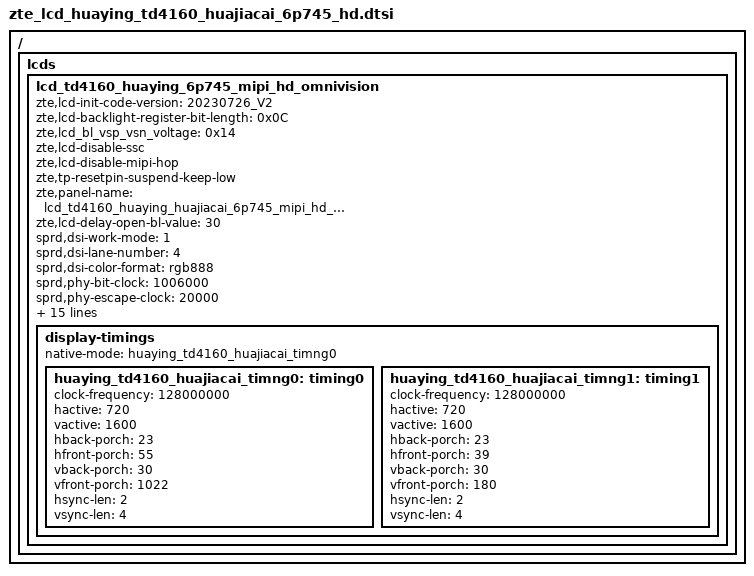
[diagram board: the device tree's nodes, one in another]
/ {
	fragment {
		target-path = "/";
		__overlay__ {
lcds {
		lcd_td4160_huaying_6p745_mipi_hd_omnivision: lcd_td4160_huaying_6p745_mipi_hd_omnivision {
			zte,lcd-init-code-version = "20230726_V2";
			zte,lcd-backlight-register-bit-length = <0x0C>;
			zte,lcd_bl_vsp_vsn_voltage = <0x14>;
			zte,lcd-disable-ssc;
			zte,lcd-disable-mipi-hop;
			zte,tp-resetpin-suspend-keep-low;
			zte,panel-name = "lcd_td4160_huaying_huajiacai_6p745_mipi_hd_omnivision";
			zte,lcd-delay-open-bl-value = <30>;

			sprd,dsi-work-mode = <1>; /* video burst mode*/
			sprd,dsi-lane-number = <4>;
			sprd,dsi-color-format = "rgb888";

			sprd,phy-bit-clock = <1006000>;	/* kbps */
			sprd,phy-escape-clock = <20000>;/* kHz */

			/*sprd,video-lp-cmd-enable = <1>;
			sprd,hporch-lp-disable = <1>;
			sprd,dpi-clk-div = <6>;*/

			sprd,width-mm = <70308>;
			sprd,height-mm = <156240>;

			sprd,esd-check-enable = <1>;/* 0:close , 1:open */
			sprd,esd-check-mode = <1>;/* 0:REG ,1:TE  */
			sprd,esd-check-period = <2000>;
			sprd,esd-check-register = <0x0A>;
			sprd,esd-check-value = <0x9C>;

			sprd,reset-on-sequence = <1 5>, <0 10>, <1 35>;
			sprd,reset-off-sequence = <0 5>;

			//sprd,use-dcs-write;
			sprd,initial-command = [
39 00 00 02 B0 00
39 00 00 07 B6 30 6A 00 86 C3 03
39 00 00 05 B7 31 00 00 00
39 00 00 07 B8 00 78 64 10 64 B4
39 00 00 07 B9 00 78 64 10 64 B4
39 00 00 07 BA 00 78 64 10 64 B4
39 00 00 04 BB 00 B4 A0
39 00 00 04 BC 00 B4 A0
39 00 00 04 BD 00 B4 A0
39 00 00 0E BE 07 00 00 00 00 00 00 00 00 00 00 00 00
39 00 00 19 C0 00 5F 22 06 40 00 1E 06 94 00 70 00 00 00 00 00 00 00 00 00 00 00 00 00
39 00 00 28 C1 30 41 50 FA 01 00 00 10 00 00 00 00 40 0F 00 00 00 00 00 00 00 00 00 00 00 00 00 00 00 00 00 00 00 00 00 00 00 00 00
39 00 00 F5 C2 05 80 58 12 0A 10 09 14 00 05 80 58 12 0A 10 07 13 00 05 80 58 12 05 06 5D 12 00 05 80 58 12 05 06 61 11 00 00 00 00 00 00 00 05 80 58 10 10 03 01 41 00 26 5F 00 00 00 08 00 00 00 00 11 00 26 5F 10 00 00 00 00 00 00 00 00 05 80 58 10 10 05 01 41 00 46 5D 00 00 00 08 00 00 00 00 11 00 46 5D 10 00 00 00 00 00 00 00 00 00 00 00 00 00 00 00 00 00 00 00 00 00 00 00 00 00 00 00 11 00 00 00 00 00 00 00 00 00 00 00 00 00 00 00 00 00 00 00 00 00 00 00 00 00 00 00 00 00 00 00 11 00 00 00 00 00 00 00 00 00 00 00 00 00 00 00 00 00 00 00 00 00 00 00 00 00 00 00 00 00 00 00 00 00 00 00 00 00 00 00 10 00 00 00 00 00 00 00 00 00 00 00 00 00 00 00 02 00 00 00 00 00 00 00 00 00 00 02 00 00 00 00 00 00 00 00 00 00 00 00 00 00 00 00 00 00 00
39 00 00 6A C3 00 00 41 81 01 06 69 00 00 00 20 00 00 00 41 81 01 66 75 00 00 00 20 02 00 00 42 81 00 F6 69 00 00 00 20 00 00 00 00 00 00 00 00 00 00 00 20 00 00 00 00 08 00 00 00 00 00 00 00 00 00 00 00 00 00 00 00 00 00 00 00 00 00 00 00 00 00 00 00 00 00 00 00 00 00 00 00 00 00 00 00 00 00 00 00 00 00 00 00 00 00 00 00 00 00
39 00 00 55 C4 00 00 0B 0F 00 00 00 00 00 00 54 53 00 21 1F 1D 1B 19 17 15 13 07 03 04 08 14 16 18 1A 1C 1E 20 22 00 53 54 00 00 00 00 00 00 10 0C 00 00 00 00 00 00 00 00 00 00 00 00 00 00 00 00 00 00 00 00 00 00 00 00 00 00 00 00 00 55 55 55 55 55 55 55 55 55 55 55
39 00 00 06 C5 08 00 00 00 00
39 00 00 4D C6 00 00 00 00 01 22 04 22 01 00 46 00 00 00 01 00 46 00 01 05 01 0B 01 35 FF 8F 06 C5 02 C0 0F 00 00 00 00 00 00 00 00 00 00 00 00 00 00 00 00 00 00 00 00 00 00 20 20 00 00 00 C0 11 00 00 00 10 10 00 00 00 01 00 50 00 33 03 00 00
39 00 00 1F CB 02 D0 01 80 00 00 00 00 00 00 00 00 00 00 00 00 00 00 00 00 00 00 40 70 00 00 00 00 00 FF
39 00 00 19 CE 5D 40 43 49 55 62 71 82 94 A8 B9 CB DB E9 F5 FC FF 04 00 04 04 00 00 00
39 00 00 02 CF 00
39 00 00 15 D0 C1 3C 81 66 09 90 00 D5 92 9F 11 1E 06 7E 09 08 DC 1B F0 06
39 00 00 26 D1 D4 D4 1B 33 33 17 07 BB 22 52 22 52 00 3B 77 07 3B 30 06 72 33 13 00 D7 0C 22 02 00 18 70 18 77 11 11 11 20 20
39 00 00 04 D2 00 00 00
39 00 00 9A D3 00 00 00 00 00 00 00 00 00 FF F7 FF FF F7 FF FF F7 FF FF F7 FF FF F7 FF FF F7 FF FF F7 FF FF F7 FF FF F7 FF FF F7 FF FF F7 FF FF F7 FF FF F7 FF FF F7 FF FF F7 FF FF F7 FF FF F7 FF FF F7 FF FF F7 FF FF F7 FF FF F7 FF FF F7 FF FF F7 FF FF F7 FF FF F7 FF FF F7 FF FF F7 FF FF F7 FF FF F7 FF FF F7 FF FF F7 FF FF F7 FF FF F7 FF FF F7 FF FF F7 FF FF F7 FF FF F7 FF FF F7 FF FF F7 FF FF F7 FF FF F7 FF FF F7 FF FF F7 FF FF F7 FF FF F7 FF FF F7 FF FF F7 FF FF F7 FF
39 00 00 18 D4 00 00 00 00 00 00 00 00 00 20 00 00 00 00 20 00 00 00 00 00 00 00 00
39 00 00 2F D7 01 00 12 12 00 90 00 18 00 90 00 18 03 83 80 85 85 85 87 84 45 86 87 80 88 86 89 83 83 87 84 88 8A 0C 0B 0A 0A 0A 07 07 06 06 00 08 0A 0A
39 00 00 17 D8 40 99 26 ED 16 6C 16 6C 16 6C 00 14 00 14 00 14 01 0C 00 00 01 00
39 00 00 29 D9 01 02 7F 36 00 00 28 00 14 00 0F 00 00 00 00 C0 00 00 00 00 00 00 00 00 00 00 00 00 00 00 00 00 0A 00 00 00 00 00 00 00
39 00 00 05 DD 30 06 23 65
39 00 00 0F DE 00 00 00 0F FF 00 00 00 00 10 00 00 00 00
39 00 00 09 E6 00 00 00 00 00 00 00 00
39 00 00 24 EA 02 07 07 04 80 10 01 00 00 00 00 03 23 00 07 00 ED 00 ED 00 ED 01 28 01 28 00 47 00 47 00 47 01 0F 01 00
39 00 00 09 EB 08 A0 61 00 01 01 00 00
39 00 00 18 EC 02 D0 01 70 73 10 01 00 00 00 00 02 2A 00 00 00 00 00 00 00 00 00 00
39 00 00 22 ED 01 02 00 00 00 00 00 00 68 27 0B 00 00 00 00 00 00 00 00 00 00 00 02 B0 00 00 00 00 00 00 40 10 00
39 00 00 7A EE 05 00 05 00 00 03 00 00 03 00 00 03 00 00 03 00 00 03 00 00 00 00 00 00 03 00 00 00 00 00 00 03 00 00 00 00 00 00 03 00 00 00 00 00 00 03 40 00 57 00 00 00 00 00 40 03 00 00 00 00 40 00 03 00 00 00 00 00 00 03 00 00 00 00 00 00 03 00 00 03 00 00 03 00 00 03 00 00 03 00 00 03 00 00 03 00 00 00 00 00 00 00 00 00 00 00 00 00 00 00 00 00 00 00 00 00 00 00 00 00 02
39 00 00 02 B0 03
29 00 00 02 35 00
05 78 00 01 11
05 32 00 01 29
				];

			sprd,sleep-in-command = [
				15 0A 00 01 28
				15 78 00 01 10
				];

			sprd,sleep-out-command = [
				15 78 00 01 11
				15 32 00 01 29
				];

			display-timings {
				native-mode = <&huaying_td4160_huajiacai_timng0>;
				huaying_td4160_huajiacai_timng0: timing0 {
					clock-frequency = <128000000>;
					hactive = <720>;
					vactive = <1600>;
					hback-porch = <23>;
					hfront-porch = <55>;
					vback-porch = <30>;
					vfront-porch = <1022>;
					hsync-len = <2>;
					vsync-len = <4>;
				};
				huaying_td4160_huajiacai_timng1: timing1 {
					clock-frequency = <128000000>;
					hactive = <720>;
					vactive = <1600>;
					hback-porch = <23>;
					hfront-porch = <39>;
					vback-porch = <30>;
					vfront-porch = <180>;
					hsync-len = <2>;
					vsync-len = <4>;
				};
			};
		};
	};
};
};};

